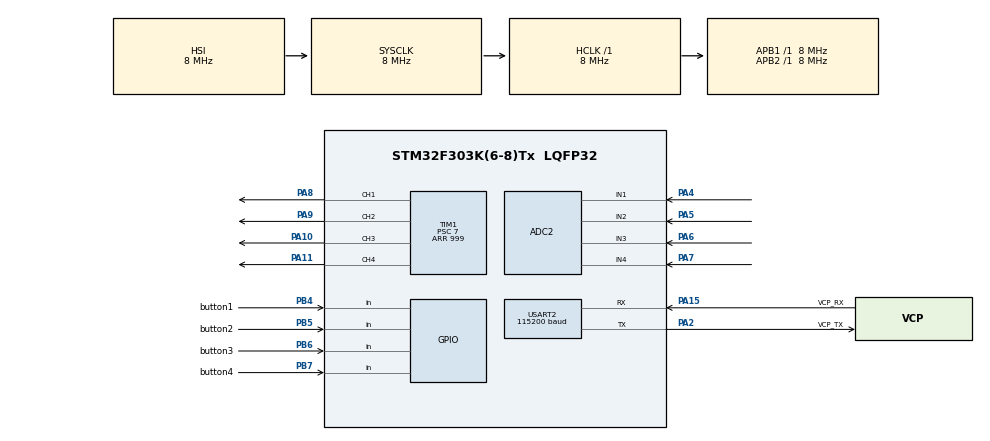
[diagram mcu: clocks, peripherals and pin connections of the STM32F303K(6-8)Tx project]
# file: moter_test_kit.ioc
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ADC2.Channel-0\#ChannelRegularConversion=ADC_CHANNEL_1
ADC2.Channel-1\#ChannelRegularConversion=ADC_CHANNEL_1
ADC2.ClockPrescaler=ADC_CLOCK_SYNC_PCLK_DIV4
ADC2.ContinuousConvMode=ENABLE
ADC2.DMAContinuousRequests=ENABLE
ADC2.EnableInjectedConversion=DISABLE
ADC2.NbrOfConversion=2
ADC2.NbrOfConversionFlag=1
ADC2.Offset-0\#ChannelRegularConversion=0
ADC2.Offset-1\#ChannelRegularConversion=0
ADC2.OffsetNumber-0\#ChannelRegularConversion=ADC_OFFSET_NONE
ADC2.OffsetNumber-1\#ChannelRegularConversion=ADC_OFFSET_NONE
ADC2.Rank-0\#ChannelRegularConversion=1
ADC2.Rank-1\#ChannelRegularConversion=2
ADC2.SamplingTime-0\#ChannelRegularConversion=ADC_SAMPLETIME_181CYCLES_5
ADC2.SamplingTime-1\#ChannelRegularConversion=ADC_SAMPLETIME_181CYCLES_5
ADC2.SamplingTimeOPAMP-1\#ChannelRegularConversion=ADC_SAMPLETIME_1CYCLE_5
ADC2.SingleDiff-0\#ChannelRegularConversion=ADC_DIFFERENTIAL_ENDED
ADC2.SingleDiff-1\#ChannelRegularConversion=ADC_DIFFERENTIAL_ENDED
ADC2.SubFamily=STM32F303x8
Dma.ADC2.0.Direction=DMA_PERIPH_TO_MEMORY
Dma.ADC2.0.Instance=DMA1_Channel2
Dma.ADC2.0.MemDataAlignment=DMA_MDATAALIGN_HALFWORD
Dma.ADC2.0.MemInc=DMA_MINC_ENABLE
Dma.ADC2.0.Mode=DMA_CIRCULAR
Dma.ADC2.0.PeriphDataAlignment=DMA_PDATAALIGN_HALFWORD
Dma.ADC2.0.PeriphInc=DMA_PINC_DISABLE
Dma.ADC2.0.Priority=DMA_PRIORITY_LOW
Dma.Request0=ADC2
Mcu.Family=STM32F3
Mcu.Name=STM32F303K(6-8)Tx
Mcu.Package=LQFP32
NVIC.DMA1_Channel2_IRQn=true\:0\:0\:false\:false\:true\:false\:true\:true
NVIC.PriorityGroup=NVIC_PRIORITYGROUP_4
PA10.Signal=S_TIM1_CH3
PA11.Signal=S_TIM1_CH4
PA13.GPIO_Label=SWDIO
PA13.Mode=Serial_Wire
PA13.Signal=SYS_JTMS-SWDIO
PA14.GPIO_Label=SWCLK
PA14.Mode=Serial_Wire
PA14.Signal=SYS_JTCK-SWCLK
PA15.GPIO_Label=VCP_RX
PA15.Mode=Asynchronous
PA15.Signal=USART2_RX
PA2.GPIO_Label=VCP_TX
PA2.Mode=Asynchronous
PA2.Signal=USART2_TX
PA4.Mode=IN1-Differential
PA4.Signal=ADC2_IN1
PA5.Mode=IN1-Differential
PA5.Signal=ADC2_IN2
PA6.Mode=IN3-Differential
PA6.Signal=ADC2_IN3
PA7.Mode=IN3-Differential
PA7.Signal=ADC2_IN4
PA8.Signal=S_TIM1_CH1
PA9.Signal=S_TIM1_CH2
PB4.GPIO_Label=button1
PB4.GPIO_PuPd=GPIO_PULLUP
PB4.Signal=GPIO_Input
PB5.GPIO_Label=button2
PB5.GPIO_PuPd=GPIO_PULLUP
PB5.Signal=GPIO_Input
PB6.GPIO_Label=button3
PB6.GPIO_PuPd=GPIO_PULLUP
PB6.Signal=GPIO_Input
PB7.GPIO_Label=button4
PB7.GPIO_PuPd=GPIO_PULLUP
PB7.Signal=GPIO_Input
PF0\ /\ OSC_IN.GPIO_Label=MCO
PF0\ /\ OSC_IN.Mode=HSE-External-Clock-Source
PF0\ /\ OSC_IN.Signal=RCC_OSC_IN
ProjectManager.HeapSize=0x200
ProjectManager.StackSize=0x400
ProjectManager.TargetToolchain=CMake
RCC.AHBFreq_Value=8000000
RCC.APB1Freq_Value=8000000
RCC.APB2Freq_Value=8000000
RCC.CortexFreq_Value=8000000
RCC.HSE_VALUE=8000000
RCC.HSI_VALUE=8000000
RCC.SYSCLKFreq_VALUE=8000000
SH.S_TIM1_CH1.0=TIM1_CH1,PWM Generation1 CH1
SH.S_TIM1_CH2.0=TIM1_CH2,PWM Generation2 CH2
SH.S_TIM1_CH3.0=TIM1_CH3,PWM Generation3 CH3
SH.S_TIM1_CH4.0=TIM1_CH4,PWM Generation4 CH4
TIM1.Channel-PWM\ Generation1\ CH1=TIM_CHANNEL_1
TIM1.Channel-PWM\ Generation2\ CH2=TIM_CHANNEL_2
TIM1.Channel-PWM\ Generation3\ CH3=TIM_CHANNEL_3
TIM1.Channel-PWM\ Generation4\ CH4=TIM_CHANNEL_4
TIM1.Period=999
TIM1.Prescaler=7
USART2.BaudRate=115200
USART2.VirtualMode-Asynchronous=VM_ASYNC
board=NUCLEO-F303K8

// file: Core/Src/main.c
/* USER CODE BEGIN Header */
/**
  ******************************************************************************
  * @file           : main.c
  * @brief          : Main program body
  ******************************************************************************
  * @attention
  *
  * Copyright (c) 2026 STMicroelectronics.
  * All rights reserved.
  *
  * This software is licensed under terms that can be found in the LICENSE file
  * in the root directory of this software component.
  * If no LICENSE file comes with this software, it is provided AS-IS.
  *
  ******************************************************************************
  */
/* USER CODE END Header */
#include "main.h"
#include "stm32f3xx_hal_tim.h"
#include <stdint.h>

/* USER CODE BEGIN PD */
#define NUM_OF_MOTOR 4 // Number of motors to control
/* USER CODE END PD */

ADC_HandleTypeDef hadc2;
DMA_HandleTypeDef hdma_adc2;

TIM_HandleTypeDef htim1;

UART_HandleTypeDef huart2;

/* USER CODE BEGIN PV */
static uint16_t adc_values[NUM_OF_MOTOR]; // Array to store ADC values for variable resistors

typedef struct {
  uint8_t button = 0; // 0: not pressed, 1: pressed
  uint16_t pwm_value = 0; // PWM value for motor speed control (0-1000 for TIM1 with period 1000)
} moter;
moter motors[NUM_OF_MOTOR]; // Array to store button states and PWM values for 4 motors
/* USER CODE END PV */

void SystemClock_Config(void);
static void MX_GPIO_Init(void);
static void MX_DMA_Init(void);
static void MX_USART2_UART_Init(void);
static void MX_ADC2_Init(void);
static void MX_TIM1_Init(void);

int main(void)
{

  /* MCU Configuration--------------------------------------------------------*/

  /* Reset of all peripherals, Initializes the Flash interface and the Systick. */
  HAL_Init();

  /* Configure the system clock */
  SystemClock_Config();

  /* Initialize all configured peripherals */
  MX_GPIO_Init();
  MX_DMA_Init();
  MX_USART2_UART_Init();
  MX_ADC2_Init();
  MX_TIM1_Init();
  /* USER CODE BEGIN 2 */
  HAL_TIM_PWM_Start(&htim1, TIM_CHANNEL_ALL);
  HAL_ADC_Start_DMA(&hadc2, (uint32_t*)adc_values, NUM_OF_MOTOR); // Start ADC in DMA mode to read variable resistors

  /* USER CODE END 2 */

  /* Infinite loop */
  while (1)
  {
    for(int i = 0; i < NUM_OF_MOTOR; i++) {
      // Read button state (active low)
      motors[i].button = (HAL_GPIO_ReadPin(GPIOB, GPIO_PIN_0 << i) == GPIO_PIN_RESET) ? 1 : 0;

      // Map ADC value (0-4095) to PWM value (0-1000)
      motors[i].pwm_value = (adc_values[i] * 1000) / 4095;

      // If button is pressed, set PWM to the mapped value, otherwise set it to 0
      __HAL_TIM_SET_COMPARE(&htim1, TIM_CHANNEL_1 << i, motors[i].button ? motors[i].pwm_value : 0);
    }
  }
}

void SystemClock_Config(void)
{
  RCC_OscInitTypeDef RCC_OscInitStruct = {0};
  RCC_ClkInitTypeDef RCC_ClkInitStruct = {0};
  RCC_PeriphCLKInitTypeDef PeriphClkInit = {0};

  /** Initializes the RCC Oscillators according to the specified parameters
  * in the RCC_OscInitTypeDef structure.
  */
  RCC_OscInitStruct.OscillatorType = RCC_OSCILLATORTYPE_HSI;
  RCC_OscInitStruct.HSIState = RCC_HSI_ON;
  RCC_OscInitStruct.HSICalibrationValue = RCC_HSICALIBRATION_DEFAULT;
  RCC_OscInitStruct.PLL.PLLState = RCC_PLL_NONE;
  if (HAL_RCC_OscConfig(&RCC_OscInitStruct) != HAL_OK)
  {
    Error_Handler();
  }

  /** Initializes the CPU, AHB and APB buses clocks
  */
  RCC_ClkInitStruct.ClockType = RCC_CLOCKTYPE_HCLK|RCC_CLOCKTYPE_SYSCLK
                              |RCC_CLOCKTYPE_PCLK1|RCC_CLOCKTYPE_PCLK2;
  RCC_ClkInitStruct.SYSCLKSource = RCC_SYSCLKSOURCE_HSI;
  RCC_ClkInitStruct.AHBCLKDivider = RCC_SYSCLK_DIV1;
  RCC_ClkInitStruct.APB1CLKDivider = RCC_HCLK_DIV1;
  RCC_ClkInitStruct.APB2CLKDivider = RCC_HCLK_DIV1;

  if (HAL_RCC_ClockConfig(&RCC_ClkInitStruct, FLASH_LATENCY_0) != HAL_OK)
  {
    Error_Handler();
  }
  PeriphClkInit.PeriphClockSelection = RCC_PERIPHCLK_TIM1;
  PeriphClkInit.Tim1ClockSelection = RCC_TIM1CLK_HCLK;
  if (HAL_RCCEx_PeriphCLKConfig(&PeriphClkInit) != HAL_OK)
  {
    Error_Handler();
  }
}

static void MX_ADC2_Init(void)
{

  ADC_ChannelConfTypeDef sConfig = {0};

  /** Common config
  */
  hadc2.Instance = ADC2;
  hadc2.Init.ClockPrescaler = ADC_CLOCK_SYNC_PCLK_DIV4;
  hadc2.Init.Resolution = ADC_RESOLUTION_12B;
  hadc2.Init.ScanConvMode = ADC_SCAN_ENABLE;
  hadc2.Init.ContinuousConvMode = ENABLE;
  hadc2.Init.DiscontinuousConvMode = DISABLE;
  hadc2.Init.ExternalTrigConvEdge = ADC_EXTERNALTRIGCONVEDGE_NONE;
  hadc2.Init.ExternalTrigConv = ADC_SOFTWARE_START;
  hadc2.Init.DataAlign = ADC_DATAALIGN_RIGHT;
  hadc2.Init.NbrOfConversion = 2;
  hadc2.Init.DMAContinuousRequests = ENABLE;
  hadc2.Init.EOCSelection = ADC_EOC_SINGLE_CONV;
  hadc2.Init.LowPowerAutoWait = DISABLE;
  hadc2.Init.Overrun = ADC_OVR_DATA_OVERWRITTEN;
  if (HAL_ADC_Init(&hadc2) != HAL_OK)
  {
    Error_Handler();
  }

  /** Configure Regular Channel
  */
  sConfig.Channel = ADC_CHANNEL_1;
  sConfig.Rank = ADC_REGULAR_RANK_1;
  sConfig.SingleDiff = ADC_DIFFERENTIAL_ENDED;
  sConfig.SamplingTime = ADC_SAMPLETIME_181CYCLES_5;
  sConfig.OffsetNumber = ADC_OFFSET_NONE;
  sConfig.Offset = 0;
  if (HAL_ADC_ConfigChannel(&hadc2, &sConfig) != HAL_OK)
  {
    Error_Handler();
  }

  /** Configure Regular Channel
  */
  sConfig.Rank = ADC_REGULAR_RANK_2;
  if (HAL_ADC_ConfigChannel(&hadc2, &sConfig) != HAL_OK)
  {
    Error_Handler();
  }

}

static void MX_TIM1_Init(void)
{

  TIM_MasterConfigTypeDef sMasterConfig = {0};
  TIM_OC_InitTypeDef sConfigOC = {0};
  TIM_BreakDeadTimeConfigTypeDef sBreakDeadTimeConfig = {0};

  htim1.Instance = TIM1;
  htim1.Init.Prescaler = 7;
  htim1.Init.CounterMode = TIM_COUNTERMODE_UP;
  htim1.Init.Period = 999;
  htim1.Init.ClockDivision = TIM_CLOCKDIVISION_DIV1;
  htim1.Init.RepetitionCounter = 0;
  htim1.Init.AutoReloadPreload = TIM_AUTORELOAD_PRELOAD_DISABLE;
  if (HAL_TIM_PWM_Init(&htim1) != HAL_OK)
  {
    Error_Handler();
  }
  sMasterConfig.MasterOutputTrigger = TIM_TRGO_RESET;
  sMasterConfig.MasterOutputTrigger2 = TIM_TRGO2_RESET;
  sMasterConfig.MasterSlaveMode = TIM_MASTERSLAVEMODE_DISABLE;
  if (HAL_TIMEx_MasterConfigSynchronization(&htim1, &sMasterConfig) != HAL_OK)
  {
    Error_Handler();
  }
  sConfigOC.OCMode = TIM_OCMODE_PWM1;
  sConfigOC.Pulse = 0;
  sConfigOC.OCPolarity = TIM_OCPOLARITY_HIGH;
  sConfigOC.OCNPolarity = TIM_OCNPOLARITY_HIGH;
  sConfigOC.OCFastMode = TIM_OCFAST_DISABLE;
  sConfigOC.OCIdleState = TIM_OCIDLESTATE_RESET;
  sConfigOC.OCNIdleState = TIM_OCNIDLESTATE_RESET;
  if (HAL_TIM_PWM_ConfigChannel(&htim1, &sConfigOC, TIM_CHANNEL_1) != HAL_OK)
  {
    Error_Handler();
  }
  if (HAL_TIM_PWM_ConfigChannel(&htim1, &sConfigOC, TIM_CHANNEL_2) != HAL_OK)
  {
    Error_Handler();
  }
  if (HAL_TIM_PWM_ConfigChannel(&htim1, &sConfigOC, TIM_CHANNEL_3) != HAL_OK)
  {
    Error_Handler();
  }
  if (HAL_TIM_PWM_ConfigChannel(&htim1, &sConfigOC, TIM_CHANNEL_4) != HAL_OK)
  {
    Error_Handler();
  }
  sBreakDeadTimeConfig.OffStateRunMode = TIM_OSSR_DISABLE;
  sBreakDeadTimeConfig.OffStateIDLEMode = TIM_OSSI_DISABLE;
  sBreakDeadTimeConfig.LockLevel = TIM_LOCKLEVEL_OFF;
  sBreakDeadTimeConfig.DeadTime = 0;
  sBreakDeadTimeConfig.BreakState = TIM_BREAK_DISABLE;
  sBreakDeadTimeConfig.BreakPolarity = TIM_BREAKPOLARITY_HIGH;
  sBreakDeadTimeConfig.BreakFilter = 0;
  sBreakDeadTimeConfig.Break2State = TIM_BREAK2_DISABLE;
  sBreakDeadTimeConfig.Break2Polarity = TIM_BREAK2POLARITY_HIGH;
  sBreakDeadTimeConfig.Break2Filter = 0;
  sBreakDeadTimeConfig.AutomaticOutput = TIM_AUTOMATICOUTPUT_DISABLE;
  if (HAL_TIMEx_ConfigBreakDeadTime(&htim1, &sBreakDeadTimeConfig) != HAL_OK)
  {
    Error_Handler();
  }
  HAL_TIM_MspPostInit(&htim1);

}

static void MX_USART2_UART_Init(void)
{

  huart2.Instance = USART2;
  huart2.Init.BaudRate = 115200;
  huart2.Init.WordLength = UART_WORDLENGTH_8B;
  huart2.Init.StopBits = UART_STOPBITS_1;
  huart2.Init.Parity = UART_PARITY_NONE;
  huart2.Init.Mode = UART_MODE_TX_RX;
  huart2.Init.HwFlowCtl = UART_HWCONTROL_NONE;
  huart2.Init.OverSampling = UART_OVERSAMPLING_16;
  huart2.Init.OneBitSampling = UART_ONE_BIT_SAMPLE_DISABLE;
  huart2.AdvancedInit.AdvFeatureInit = UART_ADVFEATURE_NO_INIT;
  if (HAL_UART_Init(&huart2) != HAL_OK)
  {
    Error_Handler();
  }

}

static void MX_DMA_Init(void)
{

  /* DMA controller clock enable */
  __HAL_RCC_DMA1_CLK_ENABLE();

  /* DMA interrupt init */
  /* DMA1_Channel2_IRQn interrupt configuration */
  HAL_NVIC_SetPriority(DMA1_Channel2_IRQn, 0, 0);
  HAL_NVIC_EnableIRQ(DMA1_Channel2_IRQn);

}

static void MX_GPIO_Init(void)
{
  GPIO_InitTypeDef GPIO_InitStruct = {0};

  /* GPIO Ports Clock Enable */
  __HAL_RCC_GPIOF_CLK_ENABLE();
  __HAL_RCC_GPIOA_CLK_ENABLE();
  __HAL_RCC_GPIOB_CLK_ENABLE();

  /*Configure GPIO pins : button1_Pin button2_Pin button3_Pin button4_Pin */
  GPIO_InitStruct.Pin = button1_Pin|button2_Pin|button3_Pin|button4_Pin;
  GPIO_InitStruct.Mode = GPIO_MODE_INPUT;
  GPIO_InitStruct.Pull = GPIO_PULLUP;
  HAL_GPIO_Init(GPIOB, &GPIO_InitStruct);

}

void Error_Handler(void)
{
  __disable_irq();
  while (1)
  {
  }
}
